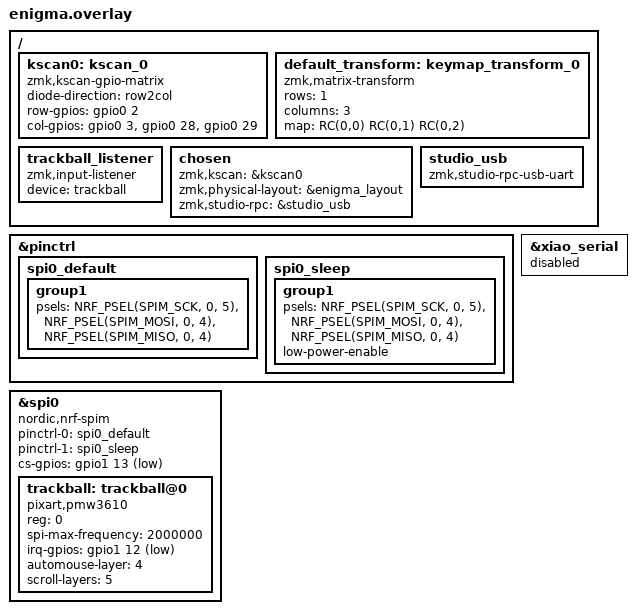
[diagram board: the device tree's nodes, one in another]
#include <zephyr/dt-bindings/dt-util.h>
#include <zephyr/dt-bindings/adc/adc.h>
#include <dt-bindings/zmk/matrix_transform.h>
#include "enigma-layouts.dtsi"

/ {
    kscan0: kscan_0 {
        compatible = "zmk,kscan-gpio-matrix";
        diode-direction = "row2col";
        row-gpios = <&gpio0 2 GPIO_ACTIVE_HIGH>;
        col-gpios = <&gpio0 3 GPIO_ACTIVE_HIGH>,
                    <&gpio0 28 GPIO_ACTIVE_HIGH>,
                    <&gpio0 29 GPIO_ACTIVE_HIGH>;
    };

    default_transform: keymap_transform_0 {
        compatible = "zmk,matrix-transform";
        rows = <1>;
        columns = <3>;
        map = <
            RC(0,0) RC(0,1) RC(0,2)
        >;
    };

    trackball_listener {
        compatible = "zmk,input-listener";
        device = <&trackball>;
    };

    chosen {
        zmk,kscan = &kscan0;
        zmk,physical-layout = &enigma_layout;
        zmk,studio-rpc = &studio_usb;
    };

    studio_usb: studio_usb {
        compatible = "zmk,studio-rpc-usb-uart";
    };
};

&pinctrl {
    spi0_default: spi0_default {
        group1 {
            psels = <NRF_PSEL(SPIM_SCK, 0, 5)>,
                    <NRF_PSEL(SPIM_MOSI, 0, 4)>,
                    <NRF_PSEL(SPIM_MISO, 0, 4)>;
        };
    };

    spi0_sleep: spi0_sleep {
        group1 {
            psels = <NRF_PSEL(SPIM_SCK, 0, 5)>,
                    <NRF_PSEL(SPIM_MOSI, 0, 4)>,
                    <NRF_PSEL(SPIM_MISO, 0, 4)>;
            low-power-enable;
        };
    };
};

&xiao_serial { 
    status = "disabled"; 
};

&spi0 {
    status = "okay";
    compatible = "nordic,nrf-spim";
    pinctrl-0 = <&spi0_default>;
    pinctrl-1 = <&spi0_sleep>;
    pinctrl-names = "default", "sleep";
    cs-gpios = <&gpio1 13 GPIO_ACTIVE_LOW>;

    trackball: trackball@0 {
        status = "okay";
        compatible = "pixart,pmw3610";
        reg = <0>;
        spi-max-frequency = <2000000>;
        irq-gpios = <&gpio1 12 (GPIO_ACTIVE_LOW | GPIO_PULL_UP)>;
        automouse-layer = <4>;
        scroll-layers = <5>;
    };
};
